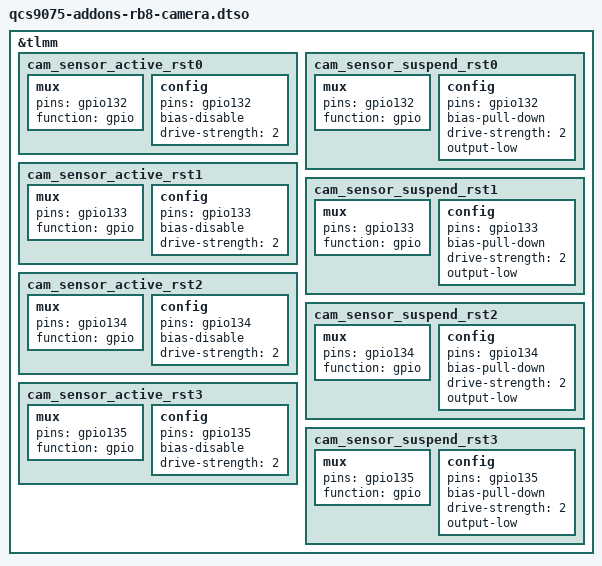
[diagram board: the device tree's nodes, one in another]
// SPDX-License-Identifier: BSD-3-Clause
/*
 * Copyright (c) 2025 Qualcomm Innovation Center, Inc. All rights reserved.
 */
/dts-v1/;
/plugin/;

#include <dt-bindings/clock/qcom,sa8775p-gcc.h>
#include <dt-bindings/clock/qcom,sa8775p-camcc.h>
#include <dt-bindings/interconnect/qcom,sa8775p-rpmh.h>
#include <dt-bindings/interrupt-controller/arm-gic.h>
#include <dt-bindings/power/qcom-rpmpd.h>

#include "sa8775p-addons-camera.dtsi"
#include "qcs9075-addons-rb8-camera-sensor.dtsi"

&tlmm {
	cam_sensor_active_rst0: cam_sensor_active_rst0 {
		/* RESET */
		mux {
			pins = "gpio132";
			function = "gpio";
		};

		config {
			pins = "gpio132";
			bias-disable; /* No PULL */
			drive-strength = <2>; /* 2 MA */
		};
	};

	cam_sensor_suspend_rst0: cam_sensor_suspend_rst0 {
		/* RESET */
		mux {
			pins = "gpio132";
			function = "gpio";
		};

		config {
			pins = "gpio132";
			bias-pull-down; /* PULL DOWN */
			drive-strength = <2>; /* 2 MA */
			output-low;
		};
	};

	cam_sensor_active_rst1: cam_sensor_active_rst1 {
		/* RESET */
		mux {
			pins = "gpio133";
			function = "gpio";
		};

		config {
			pins = "gpio133";
			bias-disable; /* No PULL */
			drive-strength = <2>; /* 2 MA */
		};
	};

	cam_sensor_suspend_rst1: cam_sensor_suspend_rst1 {
		/* RESET */
		mux {
			pins = "gpio133";
			function = "gpio";
		};

		config {
			pins = "gpio133";
			bias-pull-down; /* PULL DOWN */
			drive-strength = <2>; /* 2 MA */
			output-low;
		};
	};

	cam_sensor_active_rst2: cam_sensor_active_rst2 {
		/* RESET */
		mux {
			pins = "gpio134";
			function = "gpio";
		};

		config {
			pins = "gpio134";
			bias-disable; /* No PULL */
			drive-strength = <2>; /* 2 MA */
		};
	};

	cam_sensor_suspend_rst2: cam_sensor_suspend_rst2 {
		/* RESET */
		mux {
			pins = "gpio134";
			function = "gpio";
		};

		config {
			pins = "gpio134";
			bias-pull-down; /* PULL DOWN */
			drive-strength = <2>; /* 2 MA */
			output-low;
		};
	};

	cam_sensor_active_rst3: cam_sensor_active_rst3 {
		/* RESET */
		mux {
			pins = "gpio135";
			function = "gpio";
		};

		config {
			pins = "gpio135";
			bias-disable; /* No PULL */
			drive-strength = <2>; /* 2 MA */
		};
	};

	cam_sensor_suspend_rst3: cam_sensor_suspend_rst3 {
		/* RESET */
		mux {
			pins = "gpio135";
			function = "gpio";
		};

		config {
			pins = "gpio135";
			bias-pull-down; /* PULL DOWN */
			drive-strength = <2>; /* 2 MA */
			output-low;
		};
	};
};
